# i3c_me30 register map
Registers are access not given, no defined reset value unless marked. A register's access mark holds for its fields unless they carry their own. Offsets are from the block's base; lines under a group give offsets from that group; [hi:lo] are bit positions; {n}, {i} and the like mark numbered series; 'fields as' and 'values as' point back to an identical list; <NAME> marks a mode.

## Memory map
0x40018000 I3C size 0x1000 — I3C Registers

## Interrupts
10 I3C — I3C interrupt.

## I3C — I3C Registers
Base 0x40018000
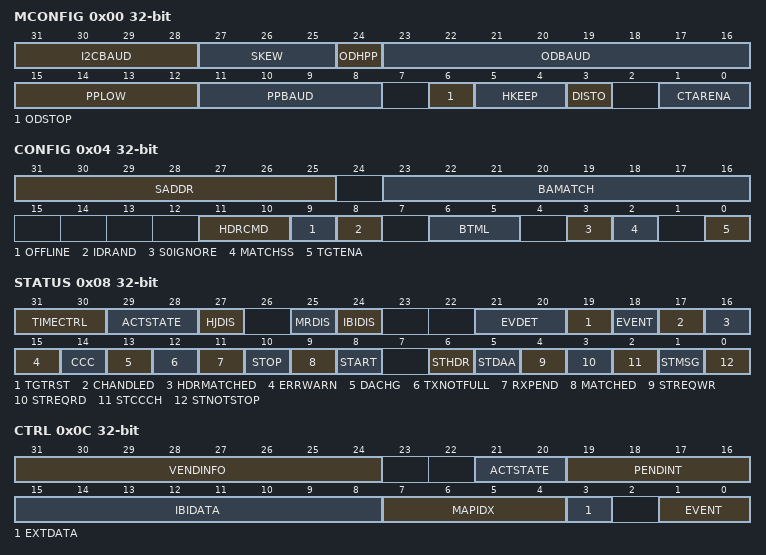
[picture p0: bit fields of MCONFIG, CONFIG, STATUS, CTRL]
0x00 MCONFIG — Controller Configuration Register
  [31:28] I2CBAUD — Determines SCL high and low periods for I2C mode, in units of ODBAUD period.
  [27:25] SKEW — Number of fclk periods to delay the SDA value change from the SCL edge for I3C push-pull operation.
    0=FCLK0 (Delay for zero fclk periods.); 1=FCLK1 (Delay for one fclk period.); 2=FCLK2 (Delay for two fclk periods.); 3=FCLK3 (Delay for three fclk periods.); 4=FCLK4 (Delay for four fclk periods.); 5=FCLK5 (Delay for five fclk periods.); 6=FCLK6 (Delay for six fclk periods.); 7=FCLK7 (Delay for seven fclk periods.)
  [24] ODHPP — Controls SCL high period for I3C open-drain operation.
  [23:16] ODBAUD — Number of PPBAUD periods (minus 1) to make one SCL low period for I3C open-drain operation.
  [15:12] PPLOW — Number of fclk periods to add to the base SCL low period for push-pull operation.
    0=FCLK0 (Add zero fclk periods to the SCL low period.); 1=FCLK1 (Add one fclk period to the SCL low period.); 2=FCLK2 (Add two fclk periods to the SCL low period.); 3=FCLK3 (Add three fclk periods to the SCL low period.); 4=FCLK4 (Add four fclk periods to the SCL low period.); 5=FCLK5 (Add five fclk periods to the SCL low period.); 6=FCLK6 (Add six fclk periods to the SCL low period.); 7=FCLK7 (Add seven fclk periods to the SCL low period.); 8=FCLK8 (Add eight fclk periods to the SCL low period.); 9=FCLK9 (Add nine fclk periods to the SCL low period.); 10=FCLK10 (Add ten fclk periods to the SCL low period.); 11=FCLK11 (Add eleven fclk periods to the SCL low period.); 12=FCLK12 (Add twelve fclk periods to the SCL low period.); 13=FCLK13 (Add thirteen fclk periods to the SCL low period.); 14=FCLK14 (Add fourteen fclk periods to the SCL low period.); 15=FCLK15 (Add fifteen fclk periods to the SCL low period.)
  [11:8] PPBAUD — SCL frequency for push-pull drive.
    0=FCLK1 (SCL high period is one fclk period.); 1=FCLK2 (SCL high period is two fclk periods.); 2=FCLK3 (SCL high period is three fclk periods.); 3=FCLK4 (SCL high period is four fclk periods.); 4=FCLK5 (SCL high period is five fclk periods.); 5=FCLK6 (SCL high period is six fclk periods.); 6=FCLK7 (SCL high period is seven fclk periods.); 7=FCLK8 (SCL high period is eight fclk periods.); 8=FCLK9 (SCL high period is nine fclk periods.); 9=FCLK10 (SCL high period is ten fclk periods.); 10=FCLK11 (SCL high period is eleven fclk periods.); 11=FCLK12 (SCL high period is twelve fclk periods.); 12=FCLK13 (SCL high period is thirteen fclk periods.); 13=FCLK14 (SCL high period is fourteen fclk periods.); 14=FCLK15 (SCL high period is fifteen fclk periods.); 15=FCLK16 (SCL high period is sixteen fclk periods.)
  [6] ODSTOP — Use open-drain speed for STOP.
    0=PUSH_PULL (The I3C_11_AC emits STOP at push-pull speed for I3C messages.); 1=OPEN_DRAIN (The I3C_11_AC emits STOP at open-drain speed for I3C messages.)
  [5:4] HKEEP — High-keeper implementation. Specifies how high-keeper control is implemented in this device.
    0=OFF (No high-keeper support.); 1=ONCHIP_SCL_SDA (On-chip high-keeper support.); 2=EXTERNAL_SDA (External high-keeper support for SDA.); 3=EXTERNAL_SCL_SDA (External high-keeper support for SCL and SDA.)
  [3] DISTO — Disable timeout error (used only when configuration parameter WITH_TIMEOUT = 1).
    0=ENABLE (Enable timeout error.); 1=DISABLE (Disable the timeout error (MERRWARN.TIMEOUT) that occurs when the controller remains in a state other than stopped for more than 100 us.)
  [1:0] CTARENA — Controller device enable.
    0=OFF (Controller mode off.); 1=ON (Controller mode on.); 2=CAPABLE (Controller mode capable.)
0x04 CONFIG — Configuration Register
  [31:25] SADDR — SADDR contains the 7-bit I2C-style static address written by the application.
  [23:16] BAMATCH — BAMATCH contains the value to be compared with the clk_slow counter value to determine when the 1-us Bus Available time has elapsed for event generation.
  [11:10] HDRCMD — HDRCMD controls whether the command byte of an incoming HDR-DDR mode message is sent to the application through the HDRCMD register or through the receive buffer/FIFO.
    0=TO_FIFO (Command byte of incoming HDR-DDR mode message is written to the receive buffer/FIFO.); 1=TO_HDRCMD (Command byte of incoming HDR-DDR mode read or write message is written to the HDRCMD register.); 2=TO_HDRCMD_FIFO (Command byte of incoming HDR-DDR mode read message is written to the HDRCMD register. Command byte of incoming HDRDDR mode write message is written to the receive buffer/FIFO.)
  [9] OFFLINE — Re-join I3C bus with existing dynamic address.
  [8] IDRAND — IDRAND contains the value for bit 32 of the 48-bit Provisioned ID, indicating whether the value in the PARTNO register is a Vendor Fixed Value or Random Value.
  [6:5] BTML — BTML specifies the number of SDA lanes to support for HDR-BT mode transfers.
    0=S_LANE (Single-lane only.); 1=SD_LANE (Single-lane or dual-lane.); 3=SDQ_LANE (Single-lane, dual-lane, or quad-lane.)
  [3] S0IGNORE — Ignore TE0 and TE1 errors.
  [2] MATCHSS — Match STOP and START.
  [0] TGTENA — Target device enable.
0x08 STATUS
  [31:30] TIMECTRL — Timing control mode.
    0=DISABLED; 1=SYNC (Timing Control Synchronous Mode is enabled.); 2=ASYNCHRONOUS (Timing Control Asynchronous Mode 0 or 1 is enabled.); 3=SYNC_ASYNC (Both Synchronous Mode and Asynchronous Mode 0 are enabled.)
  [29:28] ACTSTATE — Holds the current activity state.
    0=LATENCY_NONE (No latency.); 1=LATENCY_1MS (1 ms latency.); 2=LATENCY_100MS (100 ms latency.); 3=LATENCY_10S (10 s latency.)
  [27] HJDIS — Indicates whether Hot-Join events are disabled.
  [25] MRDIS — Indicates whether bus controller request events are disabled.
  [24] IBIDIS — Indicates whether IBI events are disabled.
  [21:20] EVDET — Holds the status of the current (when EVENT = 1) or pending event.
    0=NONE; 1=REQ_NOT_SENT (Request not yet sent.); 2=REQ_NACKED (Request was sent and NACKed and will be tried again.); 3=REQ_ACKED (Request was sent and ACKed.)
  [19] TGTRST — I3C Target Reset.
  [18] EVENT — Event requested.
  [17] CHANDLED — CCC handled.
  [16] HDRMATCHED — HDR mode address match.
  [15] ERRWARN — Error/warning.
  [14] CCC — CCC received.
  [13] DACHG — Dynamic address changed.
  [12] TXNOTFULL — Ready for to-bus (transmit) data.
  [11] RXPEND — Receive (from-bus) data ready.
  [10] STOP — STOP detected.
  [9] MATCHED — Address matched.
  [8] START — START detected.
  [6] STHDR — HDR mode.
  [5] STDAA — DAA mode.
  [4] STREQWR — SDR mode write.
  [3] STREQRD — SDR mode read.
  [2] STCCCH — CCC is being handled.
  [1] STMSG — Message.
  [0] STNOTSTOP — Not stopped.
0x0C CTRL — I3C Control Register
  [31:24] VENDINFO — Vendor Reserved field of a GETSTATUS CCC.
  [21:20] ACTSTATE — Activity Mode field of a GETSTATUS CCC.
  [19:16] PENDINT — Pending Interrupt field of a GETSTATUS CCC.
  [15:8] IBIDATA — Mandatory data byte to be sent when generating an IBI.
  [7:4] MAPIDX — Index of the dynamic address for the current IBI request.
  [3] EXTDATA — Send additional IBI data bytes data when generating an IBI.
  [1:0] EVENT — Generate event request on the I3C bus.
    0=NORMAL (Normal mode (no event requested).); 1=IBI (Generate an IBI on the I3C bus.); 2=CTLR_REQ (Request control of the I3C bus.); 3=HOTJOIN (Generate a Hot-Join request.)
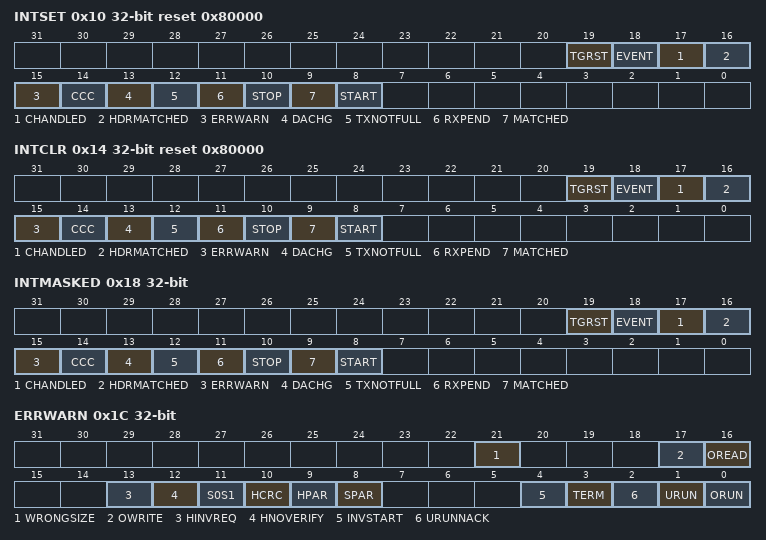
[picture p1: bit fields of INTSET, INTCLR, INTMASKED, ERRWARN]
0x10 INTSET reset 0x80000 — Interrupt Enable Set Register
  [19] TGRST — I3C target reset interrupt enable.
  [18] EVENT — Event requested interrupt enable.
  [17] CHANDLED — CCC handled interrupt enable.
  [16] HDRMATCHED — HDR address match interrupt enable.
  [15] ERRWARN — Error/warning interrupt enable.
  [14] CCC — CCC received interrupt enable.
  [13] DACHG — W1S Dynamic address changed interrupt enable.
  [12] TXNOTFULL — Ready for to-bus (transmit) data interrupt enable.
  [11] RXPEND — Receive (from-bus) data ready interrupt enable.
  [10] STOP — STOP detected interrupt enable.
  [9] MATCHED — Address matched interrupt enable.
  [8] START — START detected interrupt enable.
0x14 INTCLR wo reset 0x80000 — Interrupt Enable Clear Register
  [19] TGRST — I3C target reset interrupt disable.
  [18] EVENT — Event requested interrupt disable.
  [17] CHANDLED — CCC handled interrupt disable.
  [16] HDRMATCHED — HDR address match interrupt disable.
  [15] ERRWARN — Error/warning interrupt disable.
  [14] CCC — CCC received interrupt disable.
  [13] DACHG — W1S Dynamic address changed interrupt disable.
  [12] TXNOTFULL — Ready for to-bus (transmit) data interrupt disable.
  [11] RXPEND — Receive (from-bus) data ready interrupt disable.
  [10] STOP — STOP detected interrupt disable.
  [9] MATCHED — Address matched interrupt disable.
  [8] START — START detected interrupt disable.
0x18 INTMASKED ro — Interrupt Masked Register
  [19] TGRST — I3C target reset interrupt active.
  [18] EVENT — Event requested interrupt active.
  [17] CHANDLED — CCC handled interrupt active.
  [16] HDRMATCHED — HDR address match interrupt active.
  [15] ERRWARN — Error/warning interrupt active.
  [14] CCC — CCC received interrupt active.
  [13] DACHG — W1S Dynamic address changed interrupt active.
  [12] TXNOTFULL — Ready for to-bus (transmit) data interrupt active.
  [11] RXPEND — Receive (from-bus) data ready interrupt active.
  [10] STOP — STOP detected interrupt active.
  [9] MATCHED — Address matched interrupt active.
  [8] START — START detected interrupt active.
0x1C ERRWARN — Error and Warning Register
  [21] WRONGSIZE — Application wrote or read the wrong data register for the current mode.
  [17] OWRITE — Write data overrun.
  [16] OREAD — Read data underrun.
  [13] HINVREQ — Invalid request in HDR-BT mode.
  [12] HNOVERIFY — An HDR-BT mode read was not verified.
  [11] S0S1 — TE0 or TE1 error
  [10] HCRC — HDR CRC Error.
  [9] HPAR — HDR parity error.
  [8] SPAR — SDR parity error.
  [4] INVSTART — Invalid START.
  [3] TERM — Controller terminated read.
  [2] URUNNACK — Underrun caused NACK.
  [1] URUN — Underrun.
  [0] ORUN — Overrun.
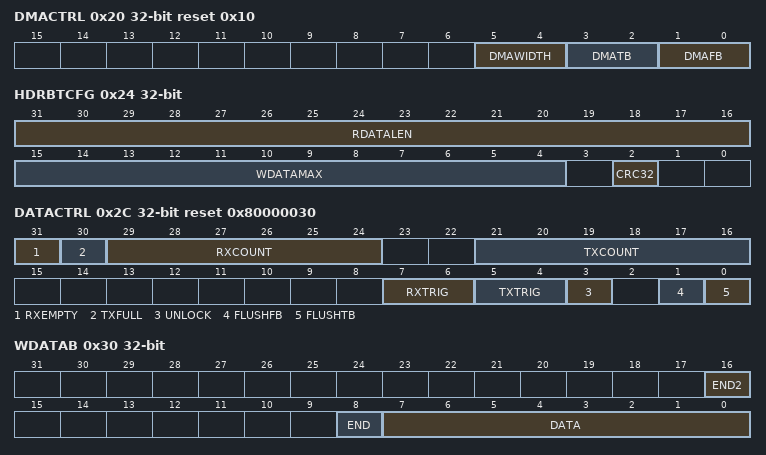
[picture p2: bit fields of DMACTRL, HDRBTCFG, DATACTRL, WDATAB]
0x20 DMACTRL reset 0x10 — DMA Control Register
  [5:4] DMAWIDTH — DMA transfer data width.
    0=BYTE; 2=HALFWORD
  [3:2] DMATB — DMA write (to-bus) enable.
    0=DISABLE (Disable DMA.); 1=EN_ONEFRAME_SDR (Enable DMA for one frame in SDR mode.); 2=ENABLE (Enable DMA until DMA is disabled by setting DMATB to 00.)
  [1:0] DMAFB — DMA read (from-bus) enable.
    0=DISABLE (Disable DMA.); 1=EN_ONEFRAME_SDR (Enable DMA for one frame in SDR mode.); 2=ENABLE (Enable DMA until DMA is disabled by setting DMAFB to 00.)
0x24 HDRBTCFG — HDR-BT Configuration Register
  [31:16] RDATALEN — Length of data to be returned for HDR-BT mode read.
  [15:4] WDATAMAX — Maximum data length for HDR-BT mode write, in units of 32-byte blocks.
  [2] CRC32 — Allow CRC32.
    0=CRC16_ONLY (Allow only CRC16.); 1=CRC32_OR_CRC16 (Allow either CRC32 or CRC16.)
0x28 HDRBTLAST ro — HDR-BT Last Data Length Register
  [31:16] DATALEN — Data length of most recent HDR-BT mode transfer.
0x2C DATACTRL reset 0x80000030 — Data Control Register
  [31] RXEMPTY — Receive buffer empty.
  [30] TXFULL — Transmit buffer full.
  [29:24] RXCOUNT — Number of entries in receive (from-bus) buffer or FIFO.
  [21:16] TXCOUNT — Number of entries in transmit (to-bus) buffer or FIFO.
  [7:6] RXTRIG — Receive (from-bus) FIFO trigger level.
    0=NOT_EMPTY (Trigger when not empty.); 1=QUARTER_FULL (Trigger when 1/4 full or more.); 2=HALF_FULL (Trigger when 1/2 full or more.); 3=3_4_FULL (Trigger when 3/4 full or more.)
  [5:4] TXTRIG — Transmit (to-bus) FIFO trigger level.
    0=EMPTY (Trigger when empty.); 1=QUARTER_FULL (Trigger when 1/4 full or less.); 2=HALF_FULL (Trigger when 1/2 full or less.); 3=ALMOST_FULL (Trigger when 1 less than full or less.)
  [3] UNLOCK — Unlock FIFO triggers.
  [1] FLUSHFB — Flush receive buffer or FIFO.
  [0] FLUSHTB — Flush transmit buffer or FIFO.
0x30 WDATAB wo — Write Byte Data Register
  [16] END2 — End-of-data.
  [8] END — End-of-data.
  [7:0] DATA — Data byte to be sent to the I3C or I2C bus controller.
0x34 WDATABE wo — Write Byte Data as End Register
  [7:0] DATA — The last data byte to be sent to the I3C bus controller for the current message.
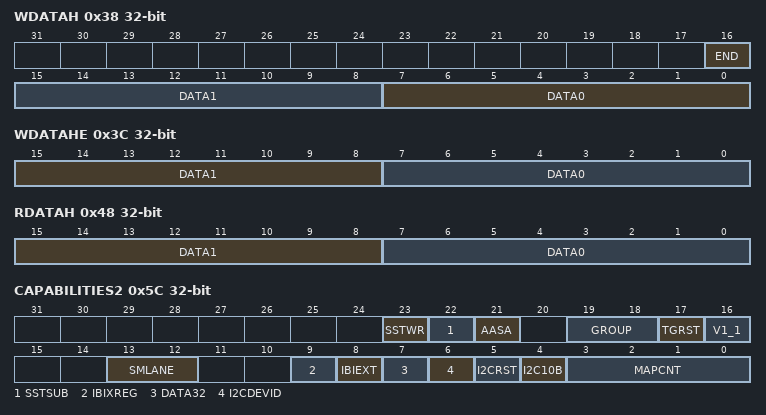
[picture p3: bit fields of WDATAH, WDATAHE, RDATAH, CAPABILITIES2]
0x38 WDATAH wo — Write Half-Word Data Register
  [16] END — Set DATA1 as the last byte of the message.
  [15:8] DATA1 — Second data byte to be sent to the I3C or I2C bus controller.
  [7:0] DATA0 — First data byte to be sent to the I3C or I2C bus controller.
0x3C WDATAHE wo — Write Half-Word Data as End Register
  [15:8] DATA1 — Second data byte to be sent to the I3C or I2C bus controller.
  [7:0] DATA0 — First data byte to be sent to the I3C or I2C bus controller.
0x40 RDATAB ro — Read Byte Data Register
  [7:0] DATA — Read data byte from receive (from-bus) buffer or FIFO.
0x48 RDATAH ro — Read Half-Word Data Register
  [15:8] DATA1 — Second read data byte from receive (from-bus) buffer or FIFO.
  [7:0] DATA0 — First read data byte from receive (from-bus) buffer or FIFO.
0x54 WDATAB1 wo — Byte-Only Write Byte Data Register
  [7:0] DATA — Data byte to be sent to the I3C bus controller.
0x5C CAPABILITIES2 ro
  [23] SSTWR — Target-to-target write support.
  [22] SSTSUB — SETAASA CCC support.
  [21] AASA — SETAASA CCC support.
  [19:18] GROUP — Group address support.
    0=NONE (Group addresses not supported.); 1=ONE (One group address supported.); 2=TWO (Two group addresses supported.); 3=THREE (Two group addresses supported.)
  [17] TGRST — I3C 1.1 Target Reset support.
  [16] V1_1 — I3C 1.1 CCC support.
  [13:12] SMLANE — Multi-lane support for HDR-BT mode.
    values as CONFIG.BTML
  [9] IBIXREG — Extended IBI data register support.
  [8] IBIEXT — Extended IBI data support.
  [7] DATA32 — 32-bit WDATAW and RDATAW registers available.
  [6] I2CDEVID — I2C device ID support.
  [5] I2CRST — I2C software reset support.
  [4] I2C10B — I2C 10-bit address support.
  [3:0] MAPCNT — Number of mapped target addresses supported.
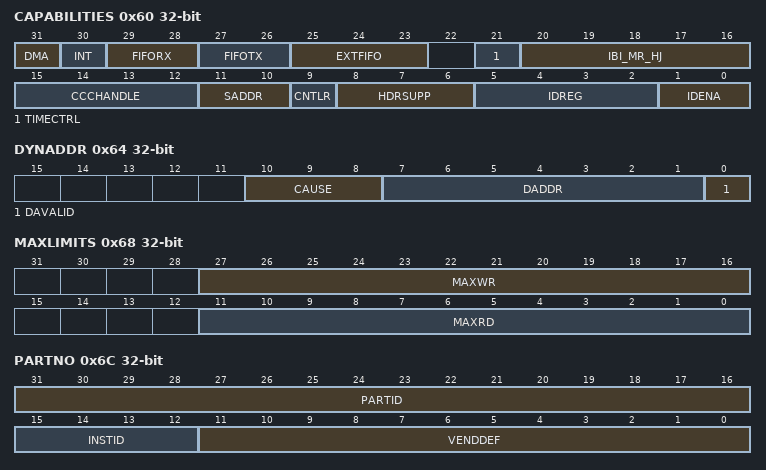
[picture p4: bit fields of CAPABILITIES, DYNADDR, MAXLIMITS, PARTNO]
0x60 CAPABILITIES ro
  [31] DMA — DMA support.
  [30] INT — Interrupt support.
  [29:28] FIFORX — Internal receive (from-bus) FIFO configuration.
    0=NONE (No internal receive FIFO.); 1=4BYTE (4-byte receive FIFO.); 2=8BYTE (8-byte receive FIFO.); 3=16BYTE (16-byte receive FIFO or larger.)
  [27:26] FIFOTX — Internal transmit (to-bus) FIFO configuration.
    0=NONE (No internal transmit FIFO.); 1=4BYTE (4-byte transmit FIFO.); 2=8BYTE (8-byte transmit FIFO.); 3=16BYTE (16-byte transmit FIFO or larger.)
  [25:23] EXTFIFO — External FIFO configuration.
  [21] TIMECTRL — Timing Control support.
  [20:16] IBI_MR_HJ — Supported events.
  [15:12] CCCHANDLE — CCCs handled by the controller.
  [11:10] SADDR — I2C-style static address implementation.
    0=NONE (No static address support.); 1=SADDR (The device has a 7-bit static address set.); 2=EXT_TGTSA (The device has a 7-bit static address set through input pin.); 3=CONFIG (The static address is software-programmable.)
  [9] CNTLR — Controller mode capable.
  [8:6] HDRSUPP — Supported HDR modes.
  [5:2] IDREG — Provisioned ID, BCR, DCR implementation.
  [1:0] IDENA — Provisioned ID implementation.
    0=PROV_PROG (Provisioned ID is programmable.); 1=PROV_SET (Provisioned ID is set by hardware parameters ID_MAN, ID_PART, ID_INST, and ID_VENDOR.); 2=INST_PROG (Provisioned ID is set by hardware parameters ID_MAN, ID_PART, and ID_VENDOR; Instance ID is programmable.); 3=PART_PROG (Manufacturer ID field is set by hardware parameter ID_MAN; Part Number field is programmable.)
0x64 DYNADDR ro — Dynamic Address Register
  [10:8] CAUSE — How the last primary dynamic address (DA) value change occurred.
    0=NO_CHANGE (No change to DA.); 1=ENTDAA (Primary DA was last assigned by ENTDAA.); 2=SETDASA_AASA_NEWDA (Primary DA was last assigned by SETDASA, SETAASA, or SETNEWDA.); 3=RSTDAA (Primary DA was cleared by RSTDAA.); 4=MAPPED_ADDR_OP (Primary DA was changed due to a mapped address related operation.)
  [7:1] DADDR — The dynamic address assigned to this I3C target device.
  [0] DAVALID — Address valid.
0x68 MAXLIMITS — Maximum Limits Register
  [27:16] MAXWR — The maximum number of bytes that the I3C bus controller may write to this I3C target device per message, with the exception of broadcast CCCs.
  [11:0] MAXRD — The maximum number of bytes that the I3C controller may read from this I3C target device per message.
0x6C PARTNO — Part Number Register
  [31:16] PARTID — Part ID field of Provisioned ID.
  [15:12] INSTID — Instance ID field of Provisioned ID.
  [11:0] VENDDEF — Vendor-defined field of Provisioned ID.
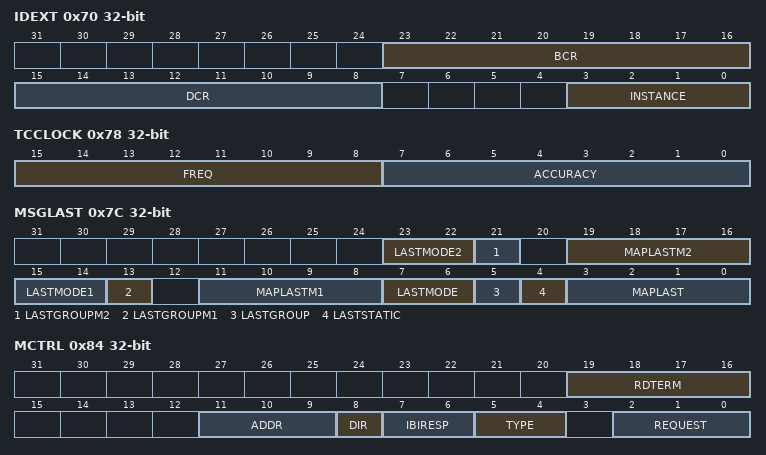
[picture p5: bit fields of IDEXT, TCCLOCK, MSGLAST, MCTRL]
0x70 IDEXT — ID Extension Register
  [23:16] BCR — BCR contains the 8-bit BCR value written by the application.
  [15:8] DCR — 8-bit DCR value written by the application.
  [3:0] INSTANCE — 4-bit Instance ID written by the application.
0x74 VENDORID
  [14:0] VID — MIPI Manufacturer ID field of the 48-bit Provisioned ID.
0x78 TCCLOCK — Timing Control Clock Register
  [15:8] FREQ — Frequency of the Timing Control clock source in 0.5-MHz units.
  [7:0] ACCURACY — Maximum variation of the Timing Control clock source in 0.1% units.
0x7C MSGLAST ro — Matching Address Index Register
  [23:22] LASTMODE2 — Mode of second previous access.
    0=I3C_SDR_OR_I2C; 1=HDRDDR; 2=HDRBT
  [21] LASTGROUPM2 — Group address indicator of second previous access.
  [19:16] MAPLASTM2 — Index or group of second previously matched address.
  [15:14] LASTMODE1
    0=I3C_SDR_OR_I2C; 1=HDRDDR; 2=HDRBT
  [13] LASTGROUPM1 — Group address indicator of previous access.
  [11:8] MAPLASTM1 — Index or group of previously matched address.
  [7:6] LASTMODE — Mode of the last access.
    0=I3C_SDR_OR_I2C; 1=HDRDDR; 2=HDRBT
  [5] LASTGROUP — The last matched address was a group address.
  [4] LASTSTATIC — Last matched address was a static address.
  [3:0] MAPLAST — Index or group number of last matched address.
0x84 MCTRL — Controller Control Register
  [19:16] RDTERM — Termination count for read.
  [11:9] ADDR — Address to send with START.
  [8] DIR — Direction of the transfer.
    0=WRITE; 1=READ
  [7:6] IBIRESP — Response to use when an IBI occurs.
  [5:4] TYPE — Controls type of operation when REQUEST = EmitStartAddr or ForceExit/Target Reset.
  [2:0] REQUEST — Requests an I3C or I2C bus operation.
    0=NONE; 1=EMIT_START_ADDR (Emit a START with address and read/write bit.); 2=EMIT_STOP (Emit a STOP.); 3=IBI_ACK_NACK (Manually ACK or NACK an IBI.); 4=PROCESS_DAA (Starts the DAA process.); 6=FORCE_EXIT_RESET (ForceExit/Target Reset.); 7=AUTO_IBI
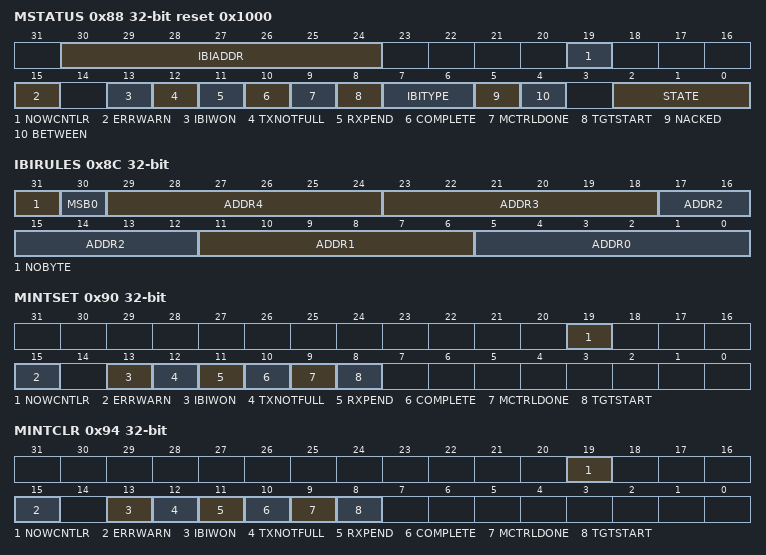
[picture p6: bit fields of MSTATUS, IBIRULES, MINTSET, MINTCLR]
0x88 MSTATUS reset 0x1000 — Controller Status Register
  [30:24] IBIADDR — The address of a received IBI or controller request.
  [19] NOWCNTLR — Controller transitioned from I3C bus target to I3C bus controller.
  [15] ERRWARN — Error/warning.
  [13] IBIWON — IBI arbitration won.
  [12] TXNOTFULL — Ready for to-bus (transmit) data.
  [11] RXPEND — Receive (from-bus) data ready.
  [10] COMPLETE — Message completed.
  [9] MCTRLDONE — MCTRL request completed.
  [8] TGTSTART — Target START detected.
  [7:6] IBITYPE — Type of event for which arbitration was last won.
    0=NONE; 1=IBI; 2=CONTROLLER_REQ (Controller request.); 3=HOTJOIN_REQ (Hot-Join request.)
  [5] NACKED — Address NACKed.
  [4] BETWEEN — Behavior of this field depends on current STATE.
  [2:0] STATE — Current working state of the I3C controller.
    0=IDLE (The I3C bus is stopped.); 1=TGTREQ (The I3C bus is stopped and a target is holding SDA low.); 2=MSGSDR (SDR message mode using MWMSG_SDR.); 3=NORMACT (SDR message mode using MCTRL, MWDATAB/H(E) and MRDATAB/H.); 4=DDR (DDR message mode initiated using either MWMSG_DDR or MCTRL.); 5=DAA (DAA mode.); 6=IBIACK (Waiting for the application to provide ACK/NACK decision.); 7=IBIRCV (Receiving an IBI.)
0x8C IBIRULES — IBI Registry and Rules Register
  [31] NOBYTE — Specifies if ADDR0-ADDR4 provide a mandatory byte when sending an IBI.
  [30] MSB0 — Implementation of MSb for I3C dynamic addresses.
    0=MAY_HAVE_MSB0 (I3C dynamic addresses may have MSb = 0 or MSb = 1.); 1=HAVE_MSB0 (All I3C dynamic addresses have MSb = 0.)
  [29:24] ADDR4 — Target 4 dynamic address.
  [6n+5:6n] ADDR{n} (n=0..3) — Target {n} dynamic address. Same function as ADDR4.
0x90 MINTSET — Controller Interrupt Enable Set Register
  [19] NOWCNTLR — Target to controller transition interrupt enable.
  [15] ERRWARN — Error/warning interrupt enable.
  [13] IBIWON — IBI arbitration won interrupt enable.
  [12] TXNOTFULL — Ready for transmit (to-bus) data interrupt enable.
  [11] RXPEND — Receive (from-bus) data ready interrupt enable.
  [10] COMPLETE — Message complete interrupt enable.
  [9] MCTRLDONE — MCTRL request completed interrupt enable.
  [8] TGTSTART — Target START detected interrupt enable.
0x94 MINTCLR wo — Controller Interrupt Enable Clear Register
  [19] NOWCNTLR — Target to controller transition interrupt disable.
  [15] ERRWARN — Error/warning interrupt disable.
  [13] IBIWON — IBI arbitration won interrupt disable.
  [12] TXNOTFULL — Ready for transmit (to-bus) data interrupt disable.
  [11] RXPEND — Receive (from-bus) data ready interrupt disable.
  [10] COMPLETE — Message complete interrupt disable.
  [9] MCTRLDONE — MCTRL request completed interrupt disable.
  [8] TGTSTART — Target START detected interrupt disable.
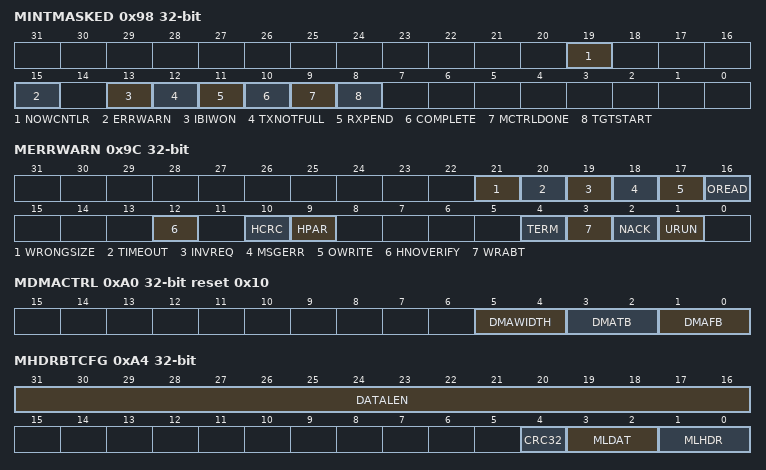
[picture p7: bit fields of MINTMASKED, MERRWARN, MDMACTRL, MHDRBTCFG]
0x98 MINTMASKED ro — Controller Interrupt Masked Register
  [19] NOWCNTLR — Target to controller transition interrupt active.
  [15] ERRWARN — Error/warning interrupt active.
  [13] IBIWON — IBI arbitration won interrupt active.
  [12] TXNOTFULL — Ready for transmit (to-bus) data interrupt active.
  [11] RXPEND — Receive (from-bus) data ready interrupt active.
  [10] COMPLETE — Message complete interrupt active.
  [9] MCTRLDONE — MCTRL request completed interrupt active.
  [8] TGTSTART — Target START detected interrupt active.
0x9C MERRWARN — Controller Error and Warning Register
  [21] WRONGSIZE
  [20] TIMEOUT — Controller timeout.
  [19] INVREQ — Invalid use of request.
  [18] MSGERR — Message mode error.
  [17] OWRITE — Write data overrun.
  [16] OREAD — Read data underrun.
  [12] HNOVERIFY — Target did not verify an HDR-BT write.
  [10] HCRC — HDR-DDR CRC error.
  [9] HPAR — HDR parity error.
  [4] TERM — Controller terminated read in message mode.
  [3] WRABT — Write aborted due to data NACK.
  [2] NACK — Address NACKed.
  [1] URUN — Transmit buffer/FIFO underrun.
0xA0 MDMACTRL reset 0x10 — Controller DMA Control Register
  [5:4] DMAWIDTH — DMA transfer data width.
    0=BYTE; 2=HALFWORD
  [3:2] DMATB — DMA write (to-bus) enable.
    0=DISABLE (Disable DMA.); 1=EN_ONEFRAME_SDR (Enable DMA for one frame.); 2=ENABLE (Enable DMA until DMA is disabled by setting DMATB to 00.)
  [1:0] DMAFB — DMA read (from-bus) enable.
    0=DISABLE (Disable DMA.); 1=EN_ONEFRAME_SDR (Enable DMA for one frame.); 2=ENABLE (Enable DMA until DMA is disabled by setting DMAFB to 00.)
0xA4 MHDRBTCFG — Controller HDR-BT Configuration Register
  [31:16] DATALEN — Data length for HDR-BT mode transfer.
  [4] CRC32 — Select CRC32 or CRC16 for an HDR-BT mode transfer.
    0=CRC16; 1=CRC32
  [3:2] MLDAT — Number of lanes to use for the data segment of an HDR-BT mode transfer.
    0=SINGLE_LANE; 1=DUAL_LANE; 3=QUAD_LANE
  [1:0] MLHDR — Number of lanes to use for the header segment of an HDR-BT mode transfer.
    0=SINGLE_LANE; 1=DUAL_LANE; 3=QUAD_LANE
0xA8 MHDRBTLAST — Controller HDR-BT Last Data Length Register
  [31:16] DATALEN — Data length of most recent HDR-BT mode transfer.
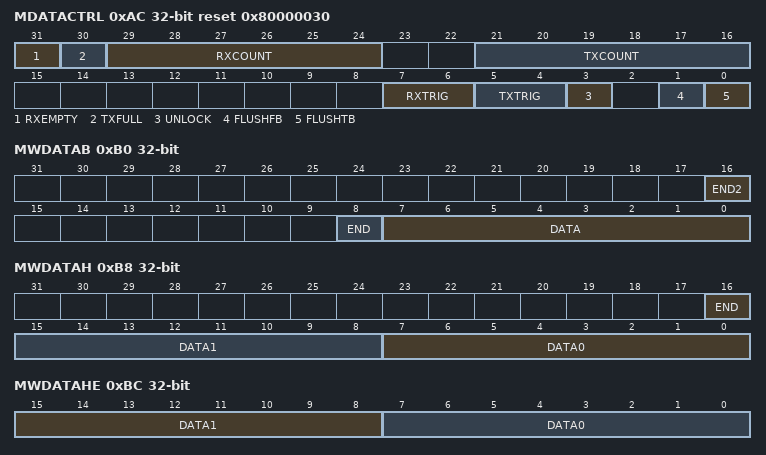
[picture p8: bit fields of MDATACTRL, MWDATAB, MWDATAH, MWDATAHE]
0xAC MDATACTRL reset 0x80000030 — Controller Data Control Register
  [31] RXEMPTY — Receive buffer empty.
  [30] TXFULL — Transmit buffer full.
  [29:24] RXCOUNT — Number of entries in receive (from-bus) buffer or FIFO.
  [21:16] TXCOUNT — Number of entries in transmit (to-bus) buffer or FIFO.
  [7:6] RXTRIG
    values as DATACTRL.RXTRIG
  [5:4] TXTRIG — Transmit (to-bus) FIFO trigger level.
    values as DATACTRL.TXTRIG
  [3] UNLOCK — Unlock FIFO triggers.
  [1] FLUSHFB — Flush receive buffer or FIFO.
  [0] FLUSHTB — Flush transmit buffer or FIFO.
0xB0 MWDATAB wo — Controller Write Byte Data Register
  [16] END2 — End-of-data.
  [8] END — End-of-data.
  [7:0] DATA — Data byte to be sent to the I3C or I2C bus.
0xB4 MWDATABE wo — Controller Write Byte Data as End Register
  [7:0] DATA — The last data byte to be sent to the I3C or I2C bus for the current message.
0xB8 MWDATAH wo — Controller Write Half-Word Data Register
  [16] END — End-of-data.
  [15:8] DATA1 — Second data byte to be sent to the I3C or I2C bus.
  [7:0] DATA0 — First data byte to be sent to the I3C or I2C bus.
0xBC MWDATAHE wo — Controller Write Half-Word Data as End Register
  [15:8] DATA1 — Second data byte to be sent to the I3C or I2C bus.
  [7:0] DATA0 — First data byte to be sent to the I3C or I2C bus.
0xC0 MRDATAB ro — Controller Read Byte Data Register
  [7:0] DATA — Read data byte from receive (from-bus) buffer or FIFO.
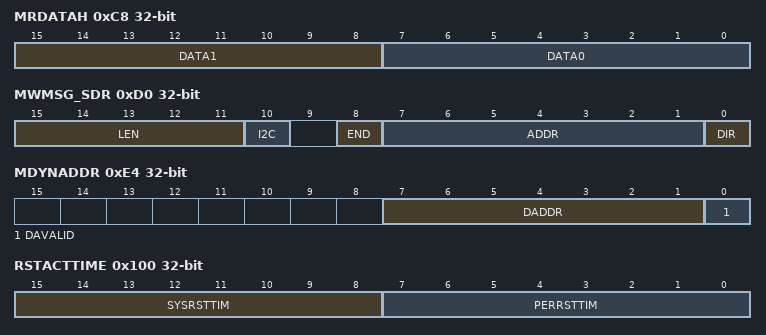
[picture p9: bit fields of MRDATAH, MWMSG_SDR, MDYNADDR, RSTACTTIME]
0xC8 MRDATAH ro — Controller Read Half-Word Data Register
  fields as RDATAH
0xCC MWDATAB1 wo — Controller Byte-Only Write Byte Data Register
  [7:0] DATA — Data byte to be transmitted I3C or I2C bus.
0xD0 MWMSG_SDR wo — Start or Continue SDR Message Register
  [15:11] LEN — Message length in bytes.
  [10] I2C — I2C mode.
    0=I2C_I3C_MODE (I3C mode.); 1=I2C_I2C_MODE (I2C mode.)
  [8] END — How to end message.
    0=WAIT_SDR (End waiting for new SDR message.); 1=STOP (End by emitting STOP.)
  [7:1] ADDR — Destination address of message.
  [0] DIR — Direction.
    0=WRITE; 1=READ
0xD4 MRMSG_SDR ro — Read SDR Message Data Register
  [15:0] DATA — Read data (16 bits).
0xD8 MWMSG_DDR wo — Start or Continue DDR Message Register
  [15:0] CONTROL_ADDRCMD_DATA — Control information, mode address and command, or data for HDR-DDR write message.
0xDC MRMSG_DDR ro — Read DDR Message Data Register
  [15:0] DATA — Read data (16 bits).
0xE4 MDYNADDR — Controller Dynamic Address Register
  [7:1] DADDR — The assigned dynamic address.
  [0] DAVALID — Address valid.
0xF0 MWDATAW wo — Controller Write Word Data Register
  [31:0] DATA — Data to be transmitted in HDR-BT mode.
0xF8 MRDATAW ro — Controller Read Word Data Register
  [31:0] DATA — Read data from receive (from-bus) FIFO.
0x100 RSTACTTIME — Target Reset Recovery Time Register
  [15:8] SYSRSTTIM — whole target reset time to be returned in response to an RSTACT CCC.
  [7:0] PERRSTTIM — I3C peripheral reset time to be returned in response to an RSTACT CCC.
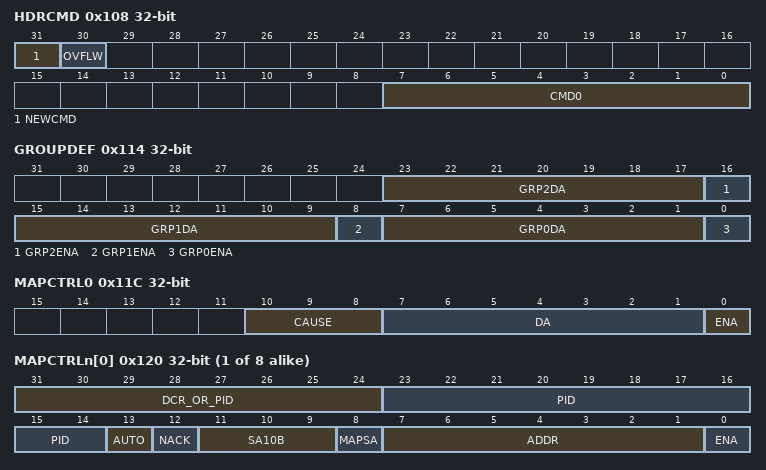
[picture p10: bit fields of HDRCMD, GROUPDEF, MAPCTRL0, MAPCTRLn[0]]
0x108 HDRCMD ro — HDR Command Byte Register
  [31] NEWCMD — New command byte stored.
  [30] OVFLW — Command byte overflow.
  [7:0] CMD0 — The HDR-DDR mode command byte from the most recently received HDR-DDR mode message.
0x114 GROUPDEF ro — Group Definition Register
  [23:17] GRP2DA — The assigned address for group address 2.
  [16] GRP2ENA — Group address 2 enabled.
  [15:9] GRP1DA — The assigned address for group address 1.
  [8] GRP1ENA — Group address 1 enabled.
  [7:1] GRP0DA — The assigned address for group address 0.
  [0] GRP0ENA — Group address 0 enabled.
0x11C MAPCTRL0 ro — Map Control Register 0
  [10:8] CAUSE
    values as DYNADDR.CAUSE
  [7:1] DA — Primary dynamic address.
  [0] ENA — Primary dynamic address enabled.
{0x120+4i} MAPCTRLn[{i}] (i=0..7) — Map Control Register n
  [31:24] DCR_OR_PID — DCR or PID replacement fields [17:10]
  [23:14] PID — Slot-specific PID replacement bits [9:0].
  [13] AUTO — Enable slot for automatic dynamic address assignment.
  [12] NACK — NACK incoming addresses that match this mapped address.
  [11:9] SA10B — Upper 3 bits of a 10-bit I2C static address or 7-bit static or dynamic address.
  [8] MAPSA — Static address.
  [7:1] ADDR — Static or dynamic address assigned to this mapped address slot.
  [0] ENA — Slot enable.
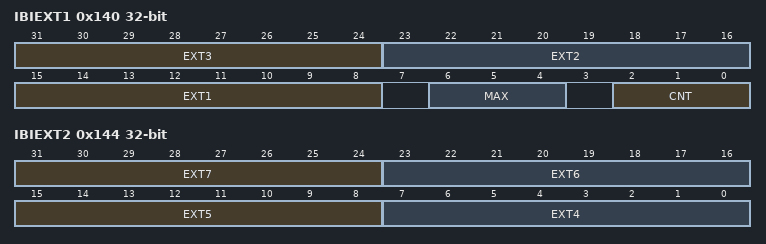
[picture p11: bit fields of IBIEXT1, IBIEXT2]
0x140 IBIEXT1 — Extended IBI Data Register 1
  [31:24] EXT3 — Third extended IBI data byte to send with an IBI.
  [23:16] EXT2 — Second extended IBI data byte to send with an IBI.
  [15:8] EXT1 — First extended IBI data byte to send with an IBI.
  [6:4] MAX — The maximum number of extended IBI data bytes that can be sent using the IBIEXT1 and IBIEXT2 registers.
  [2:0] CNT — The number of extended IBI data bytes to send from the IBIEXT1 and IBIEXT2 registers.
0x144 IBIEXT2 — Extended IBI Data Register 2
  [31:24] EXT7 — Seventh extended IBI data byte to send with an IBI.
  [23:16] EXT6 — Sixth extended IBI data byte to send with an IBI.
  [15:8] EXT5 — Fifth extended IBI data byte to send with an IBI.
  [7:0] EXT4 — Fourth extended IBI data byte to send with an IBI.
0x150 WDATAW wo — Write Word Data Register
  [31:0] DATA — Data to be transmitted in HDR-BT mode.
0x158 RDATAW ro — Read Word Data Register
  [31:0] DATA — Read data from receive (from-bus) FIFO.
0xFFC ID — Block ID Register
  [31:0] ID — Vendor-specific information set by hardware configuration parameter BLOCK_ID.
